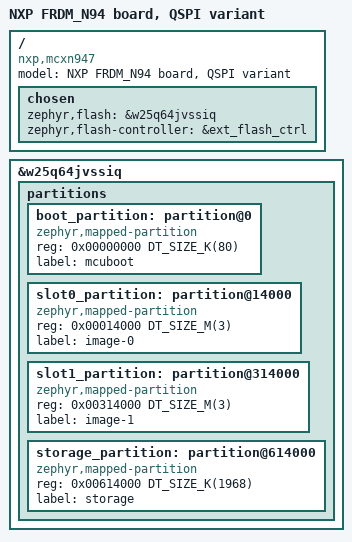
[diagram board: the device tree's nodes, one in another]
/*
 * Copyright 2024 NXP
 *
 * SPDX-License-Identifier: Apache-2.0
 */

/dts-v1/;

#include "frdm_mcxn947_mcxn947_cpu0.dtsi"

/delete-node/ &boot_partition;
/delete-node/ &slot0_partition;
/delete-node/ &slot1_partition;
/delete-node/ &storage_partition;

/ {
	compatible = "nxp,mcxn947", "nxp,mcx";
	model = "NXP FRDM_N94 board, QSPI variant";

	chosen {
		zephyr,flash = &w25q64jvssiq;
		zephyr,flash-controller = &ext_flash_ctrl;
	};
};

&w25q64jvssiq {
	partitions {
		ranges;
		#address-cells = <1>;
		#size-cells = <1>;

		boot_partition: partition@0 {
			compatible = "zephyr,mapped-partition";
			reg = <0x00000000 DT_SIZE_K(80)>;
			label = "mcuboot";
		};

		slot0_partition: partition@14000 {
			compatible = "zephyr,mapped-partition";
			reg = <0x00014000 DT_SIZE_M(3)>;
			label = "image-0";
		};

		slot1_partition: partition@314000 {
			compatible = "zephyr,mapped-partition";
			reg = <0x00314000 DT_SIZE_M(3)>;
			label = "image-1";
		};

		storage_partition: partition@614000 {
			compatible = "zephyr,mapped-partition";
			reg = <0x00614000 DT_SIZE_K(1968)>;
			label = "storage";
		};
	};
};
